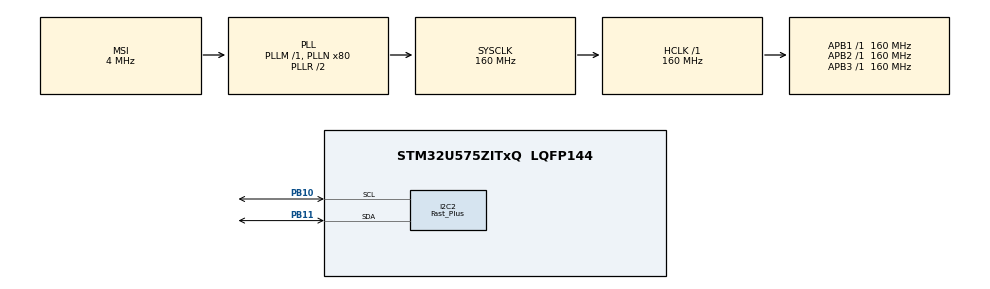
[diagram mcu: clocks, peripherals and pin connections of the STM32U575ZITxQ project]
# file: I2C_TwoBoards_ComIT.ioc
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CORTEX_M33_NS.userName=CORTEX_M33
I2C2.AddressingMode=I2C_ADDRESSINGMODE_10BIT
I2C2.Analog_Filter=I2C_ANALOGFILTER_ENABLE
I2C2.DualAddressMode=I2C_DUALADDRESS_DISABLE
I2C2.GeneralCallMode=I2C_GENERALCALL_DISABLE
I2C2.I2C_Coeff_DF=0
I2C2.I2C_Fall_Time=2
I2C2.I2C_Rise_Time=26
I2C2.I2C_Speed_Mode=I2C_Fast_Plus
I2C2.NoStretchMode=I2C_NOSTRETCH_DISABLE
I2C2.OwnAddress=I2C_ADDRESS
I2C2.Speed=1000
I2C2.Timing=0x00C01F67
Mcu.Family=STM32U5
Mcu.Name=STM32U575ZITxQ
Mcu.Package=LQFP144
Mcu.UserConstants=I2C_ADDRESS,0x30F
NVIC.I2C2_ER_IRQn=true\:0\:0\:false\:false\:true\:true\:true\:true
NVIC.I2C2_EV_IRQn=true\:0\:0\:false\:false\:true\:true\:true\:true
NVIC.PriorityGroup=NVIC_PRIORITYGROUP_4
PB10.GPIO_Pu=GPIO_PULLUP
PB10.Mode=I2C
PB10.Signal=I2C2_SCL
PB11.GPIO_Pu=GPIO_PULLUP
PB11.Mode=I2C
PB11.Signal=I2C2_SDA
PWR.PowerMode=PWR_SMPS_SUPPLY
ProjectManager.HeapSize=0x200
ProjectManager.StackSize=0x400
ProjectManager.TargetToolchain=EWARM V8.50
RCC.ADCFreq_Value=16000000
RCC.AHBFreq_Value=160000000
RCC.APB1Freq_Value=160000000
RCC.APB1TimFreq_Value=160000000
RCC.APB2Freq_Value=160000000
RCC.APB2TimFreq_Value=160000000
RCC.APB3Freq_Value=160000000
RCC.CortexFreq_Value=160000000
RCC.DACCLockSelectionVirtual=RCC_DAC1CLKSOURCE_LSI
RCC.DACCLockSelectionVirtualString=RCC_DAC1CLKSOURCE_LSI
RCC.EPOD_VALUE=4000000
RCC.HCLKFreq_Value=160000000
RCC.HSE_VALUE=16000000
RCC.HSI48_VALUE=48000000
RCC.HSI_VALUE=16000000
RCC.LSE_VALUE=32768
RCC.LSIDIV_VALUE=32000
RCC.MSI_VALUE=4000000
RCC.PLLN=80
RCC.SYSCLKFreq_VALUE=160000000
RCC.SYSCLKSource=RCC_SYSCLKSOURCE_PLLCLK
RCC.USBFreq_Value=48000000
RCC.VCOOutputFreq_Value=320000000
VP_ICACHE_VS_ICACHE.Mode=DirectMappedCache
VP_LPBAMQUEUE_VS_QUEUE.Mode=QUEUEMODE
VP_LPBAM_VS_SIG1.Mode=SmartRun
VP_LPBAM_VS_SIG4.Mode=LPDMA1
VP_PWR_VS_DBSignals.Mode=DisableDeadBatterySignals
VP_PWR_VS_LPOM.Mode=PowerOptimisation
VP_PWR_VS_SECSignals.Mode=Security/Privilege
board=custom

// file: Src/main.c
/* USER CODE BEGIN Header */
/**
  ******************************************************************************
  * @file    I2C/I2C_TwoBoards_ComIT/Src/main.c
  * @author  MCD Application Team
  * @brief   This sample code shows how to use STM32U5xx I2C HAL API to transmit
  *          and receive a data buffer with a communication process based on
  *          IT transfer.
  *          The communication is done using 2 Boards.
  ******************************************************************************
  * @attention
  *
  * Copyright (c) 2021 STMicroelectronics.
  * All rights reserved.
  *
  * This software is licensed under terms that can be found in the LICENSE file
  * in the root directory of this software component.
  * If no LICENSE file comes with this software, it is provided AS-IS.
  *
  ******************************************************************************
  */
/* USER CODE END Header */
#include "main.h"

/* USER CODE BEGIN PD */
/* Uncomment this line to use the board as master, if not it is used as slave */
//#define MASTER_BOARD
/* USER CODE END PD */

I2C_HandleTypeDef hi2c2;

/* USER CODE BEGIN PV */
/* Buffer used for transmission */
uint8_t aTxBuffer[] = " ****I2C_TwoBoards communication based on IT****  ****I2C_TwoBoards communication based on IT****  ****I2C_TwoBoards communication based on IT**** ";

/* Buffer used for reception */
uint8_t aRxBuffer[RXBUFFERSIZE];
/* USER CODE END PV */

void SystemClock_Config(void);
static void SystemPower_Config(void);
static void MX_GPIO_Init(void);
static void MX_I2C2_Init(void);
static void MX_ICACHE_Init(void);
/* USER CODE BEGIN PFP */
/* Private function prototypes -----------------------------------------------*/
static uint16_t Buffercmp(uint8_t *pBuffer1, uint8_t *pBuffer2, uint16_t BufferLength);

/* USER CODE END PFP */

int main(void)
{

  /* USER CODE BEGIN 1 */
  /* STM32U5xx HAL library initialization:
       - Configure the Flash prefetch
       - Configure the Systick to generate an interrupt each 1 msec
       - Set NVIC Group Priority to 3
       - Low Level Initialization
     */
  /* USER CODE END 1 */

  /* MCU Configuration--------------------------------------------------------*/

  /* Reset of all peripherals, Initializes the Flash interface and the Systick. */
  HAL_Init();

  /* Configure the System Power */
  SystemPower_Config();

  /* Configure the system clock */
  SystemClock_Config();

  /* Initialize all configured peripherals */
  MX_GPIO_Init();
  MX_I2C2_Init();
  MX_ICACHE_Init();
  /* USER CODE BEGIN 2 */
  /* Configure LED1 and LED3 */
  BSP_LED_Init(LED1);
  BSP_LED_Init(LED3);

#ifdef MASTER_BOARD

  /* Configure User push-button */
  BSP_PB_Init(BUTTON_USER, BUTTON_MODE_GPIO);
  /* USER CODE END 2 */

  /* Infinite loop */
  /* USER CODE BEGIN WHILE */
  /* Wait for User push-button press before starting the Communication */
  while (BSP_PB_GetState(BUTTON_USER) != GPIO_PIN_SET)
  {
  }

  /* Delay to avoid that possible signal rebound is taken as button release */
  HAL_Delay(50);

  /* Wait for User push-button release before starting the Communication */
  while (BSP_PB_GetState(BUTTON_USER) != GPIO_PIN_RESET)
  {
  }

  /* The board sends the message and expects to receive it back */

  /*##- Start the transmission process #####################################*/
  /* While the I2C in reception process, user can transmit data through
     "aTxBuffer" buffer */
  do
  {
    if (HAL_I2C_Master_Transmit_IT(&hi2c2, (uint16_t)I2C_ADDRESS, (uint8_t *)aTxBuffer, TXBUFFERSIZE) != HAL_OK)
    {
      /* Error_Handler() function is called when error occurs. */
      Error_Handler();
    }

    /*##- Wait for the end of the transfer #################################*/
    /*  Before starting a new communication transfer, you need to check the current
        state of the peripheral; if it's busy you need to wait for the end of current
        transfer before starting a new one.
        For simplicity reasons, this example is just waiting till the end of the
        transfer, but application may perform other tasks while transfer operation
        is ongoing. */
    while (HAL_I2C_GetState(&hi2c2) != HAL_I2C_STATE_READY)
    {
    }

    /* When Acknowledge failure occurs (Slave don't acknowledge it's address)
       Master restarts communication */
  }
  while (HAL_I2C_GetError(&hi2c2) == HAL_I2C_ERROR_AF);

  /* Wait for User push-button press before starting the Communication */
  while (BSP_PB_GetState(BUTTON_USER) != GPIO_PIN_SET)
  {
  }

  /* Delay to avoid that possible signal rebound is taken as button release */
  HAL_Delay(50);

  /* Wait for User push-button release before starting the Communication */
  while (BSP_PB_GetState(BUTTON_USER) != GPIO_PIN_RESET)
  {
  }

  /*##- Put I2C peripheral in reception process ###########################*/
  do
  {
    if (HAL_I2C_Master_Receive_IT(&hi2c2, (uint16_t)I2C_ADDRESS, (uint8_t *)aRxBuffer, RXBUFFERSIZE) != HAL_OK)
    {
      /* Error_Handler() function is called when error occurs. */
      Error_Handler();
    }

    /*##- Wait for the end of the transfer #################################*/
    /*  Before starting a new communication transfer, you need to check the current
        state of the peripheral; if it's busy you need to wait for the end of current
        transfer before starting a new one.
        For simplicity reasons, this example is just waiting till the end of the
        transfer, but application may perform other tasks while transfer operation
        is ongoing. */
    while (HAL_I2C_GetState(&hi2c2) != HAL_I2C_STATE_READY)
    {
    }

    /* When Acknowledge failure occurs (Slave don't acknowledge it's address)
       Master restarts communication */
  }
  while (HAL_I2C_GetError(&hi2c2) == HAL_I2C_ERROR_AF);

#else

  /* The board receives the message and sends it back */

  /*##- Put I2C peripheral in reception process ###########################*/
  if (HAL_I2C_Slave_Receive_IT(&hi2c2, (uint8_t *)aRxBuffer, RXBUFFERSIZE) != HAL_OK)
  {
    /* Transfer error in reception process */
    Error_Handler();
  }

  /*##- Wait for the end of the transfer ###################################*/
  /*  Before starting a new communication transfer, you need to check the current
      state of the peripheral; if it's busy you need to wait for the end of current
      transfer before starting a new one.
      For simplicity reasons, this example is just waiting till the end of the
      transfer, but application may perform other tasks while transfer operation
      is ongoing. */
  while (HAL_I2C_GetState(&hi2c2) != HAL_I2C_STATE_READY)
  {
  }

  /*##- Start the transmission process #####################################*/
  /* While the I2C in reception process, user can transmit data through
     "aTxBuffer" buffer */
  if (HAL_I2C_Slave_Transmit_IT(&hi2c2, (uint8_t *)aTxBuffer, TXBUFFERSIZE) != HAL_OK)
  {
    /* Transfer error in transmission process */
    Error_Handler();
  }

#endif /* MASTER_BOARD */

  /*##- Wait for the end of the transfer ###################################*/
  /*  Before starting a new communication transfer, you need to check the current
      state of the peripheral; if it's busy you need to wait for the end of current
      transfer before starting a new one.
      For simplicity reasons, this example is just waiting till the end of the
      transfer, but application may perform other tasks while transfer operation
      is ongoing. */
  while (HAL_I2C_GetState(&hi2c2) != HAL_I2C_STATE_READY)
  {
  }

  /*##- Compare the sent and received buffers ##############################*/
  if (Buffercmp((uint8_t *)aTxBuffer, (uint8_t *)aRxBuffer, RXBUFFERSIZE))
  {
    /* Processing Error */
    Error_Handler();
  }

  /* Infinite loop */
  while (1)
  {
    /* USER CODE END WHILE */

  }
}

void SystemClock_Config(void)
{
  RCC_OscInitTypeDef RCC_OscInitStruct = {0};
  RCC_ClkInitTypeDef RCC_ClkInitStruct = {0};

  /** Configure the main internal regulator output voltage
  */
  if (HAL_PWREx_ControlVoltageScaling(PWR_REGULATOR_VOLTAGE_SCALE1) != HAL_OK)
  {
    Error_Handler();
  }

  /** Initializes the CPU, AHB and APB buses clocks
  */
  RCC_OscInitStruct.OscillatorType = RCC_OSCILLATORTYPE_MSI;
  RCC_OscInitStruct.MSIState = RCC_MSI_ON;
  RCC_OscInitStruct.MSICalibrationValue = RCC_MSICALIBRATION_DEFAULT;
  RCC_OscInitStruct.MSIClockRange = RCC_MSIRANGE_4;
  RCC_OscInitStruct.PLL.PLLState = RCC_PLL_ON;
  RCC_OscInitStruct.PLL.PLLSource = RCC_PLLSOURCE_MSI;
  RCC_OscInitStruct.PLL.PLLMBOOST = RCC_PLLMBOOST_DIV1;
  RCC_OscInitStruct.PLL.PLLM = 1;
  RCC_OscInitStruct.PLL.PLLN = 80;
  RCC_OscInitStruct.PLL.PLLP = 2;
  RCC_OscInitStruct.PLL.PLLQ = 2;
  RCC_OscInitStruct.PLL.PLLR = 2;
  RCC_OscInitStruct.PLL.PLLRGE = RCC_PLLVCIRANGE_0;
  RCC_OscInitStruct.PLL.PLLFRACN = 0;
  if (HAL_RCC_OscConfig(&RCC_OscInitStruct) != HAL_OK)
  {
    Error_Handler();
  }

  /** Initializes the CPU, AHB and APB buses clocks
  */
  RCC_ClkInitStruct.ClockType = RCC_CLOCKTYPE_HCLK|RCC_CLOCKTYPE_SYSCLK
                              |RCC_CLOCKTYPE_PCLK1|RCC_CLOCKTYPE_PCLK2
                              |RCC_CLOCKTYPE_PCLK3;
  RCC_ClkInitStruct.SYSCLKSource = RCC_SYSCLKSOURCE_PLLCLK;
  RCC_ClkInitStruct.AHBCLKDivider = RCC_SYSCLK_DIV1;
  RCC_ClkInitStruct.APB1CLKDivider = RCC_HCLK_DIV1;
  RCC_ClkInitStruct.APB2CLKDivider = RCC_HCLK_DIV1;
  RCC_ClkInitStruct.APB3CLKDivider = RCC_HCLK_DIV1;

  if (HAL_RCC_ClockConfig(&RCC_ClkInitStruct, FLASH_LATENCY_4) != HAL_OK)
  {
    Error_Handler();
  }
}

/**
  * @brief Power Configuration
  * @retval None
  */
static void SystemPower_Config(void)
{

  /*
   * Disable the internal Pull-Up in Dead Battery pins of UCPD peripheral
   */
  HAL_PWREx_DisableUCPDDeadBattery();

  /*
   * Switch to SMPS regulator instead of LDO
   */
  if (HAL_PWREx_ConfigSupply(PWR_SMPS_SUPPLY) != HAL_OK)
  {
    Error_Handler();
  }
}

static void MX_I2C2_Init(void)
{

  hi2c2.Instance = I2C2;
  hi2c2.Init.Timing = 0x00C01F67;
  hi2c2.Init.OwnAddress1 = I2C_ADDRESS;
  hi2c2.Init.AddressingMode = I2C_ADDRESSINGMODE_10BIT;
  hi2c2.Init.DualAddressMode = I2C_DUALADDRESS_DISABLE;
  hi2c2.Init.OwnAddress2 = 0;
  hi2c2.Init.OwnAddress2Masks = I2C_OA2_NOMASK;
  hi2c2.Init.GeneralCallMode = I2C_GENERALCALL_DISABLE;
  hi2c2.Init.NoStretchMode = I2C_NOSTRETCH_DISABLE;
  if (HAL_I2C_Init(&hi2c2) != HAL_OK)
  {
    Error_Handler();
  }

  /** Configure Analogue filter
  */
  if (HAL_I2CEx_ConfigAnalogFilter(&hi2c2, I2C_ANALOGFILTER_ENABLE) != HAL_OK)
  {
    Error_Handler();
  }

  /** Configure Digital filter
  */
  if (HAL_I2CEx_ConfigDigitalFilter(&hi2c2, 0) != HAL_OK)
  {
    Error_Handler();
  }

  /** I2C Fast mode Plus enable
  */
  if (HAL_I2CEx_ConfigFastModePlus(&hi2c2, I2C_FASTMODEPLUS_ENABLE) != HAL_OK)
  {
    Error_Handler();
  }

}

static void MX_ICACHE_Init(void)
{

  /** Enable instruction cache in 1-way (direct mapped cache)
  */
  if (HAL_ICACHE_ConfigAssociativityMode(ICACHE_1WAY) != HAL_OK)
  {
    Error_Handler();
  }
  if (HAL_ICACHE_Enable() != HAL_OK)
  {
    Error_Handler();
  }

}

static void MX_GPIO_Init(void)
{

  /* GPIO Ports Clock Enable */
  __HAL_RCC_GPIOB_CLK_ENABLE();

}

/* USER CODE BEGIN 4 */
/**
  * @brief  Compares two buffers.
  * @param  pBuffer1, pBuffer2: buffers to be compared.
  * @param  BufferLength: buffer's length
  * @retval 0  : pBuffer1 identical to pBuffer2
  *         >0 : pBuffer1 differs from pBuffer2
  */
static uint16_t Buffercmp(uint8_t *pBuffer1, uint8_t *pBuffer2, uint16_t BufferLength)
{
  while (BufferLength--)
  {
    if ((*pBuffer1) != *pBuffer2)
    {
      return BufferLength;
    }
    pBuffer1++;
    pBuffer2++;
  }

  return 0;
}

/**
  * @brief  Tx Transfer completed callback.
  * @param  I2cHandle: I2C handle.
  * @note   This example shows a simple way to report end of IT Tx transfer, and
  *         you can add your own implementation.
  * @retval None
  */
#ifdef MASTER_BOARD
void HAL_I2C_MasterTxCpltCallback(I2C_HandleTypeDef *I2cHandle)
{
  /* Toggle LED1: Transfer in transmission process is correct */
  BSP_LED_Toggle(LED1);
}
#else
void HAL_I2C_SlaveTxCpltCallback(I2C_HandleTypeDef *I2cHandle)
{
  /* Toggle LED1: Transfer in transmission process is correct */
  BSP_LED_Toggle(LED1);
}
#endif /* MASTER_BOARD */

/**
  * @brief  Rx Transfer completed callback.
  * @param  I2cHandle: I2C handle
  * @note   This example shows a simple way to report end of IT Rx transfer, and
  *         you can add your own implementation.
  * @retval None
  */
#ifdef MASTER_BOARD
void HAL_I2C_MasterRxCpltCallback(I2C_HandleTypeDef *I2cHandle)
{
  /* Toggle LED1: Transfer in reception process is correct */
  BSP_LED_Toggle(LED1);
}
#else
void HAL_I2C_SlaveRxCpltCallback(I2C_HandleTypeDef *I2cHandle)
{
  /* Toggle LED1: Transfer in reception process is correct */
  BSP_LED_Toggle(LED1);
}
#endif /* MASTER_BOARD */

/**
  * @brief  I2C error callbacks.
  * @param  I2cHandle: I2C handle
  * @note   This example shows a simple way to report transfer error, and you can
  *         add your own implementation.
  * @retval None
  */
void HAL_I2C_ErrorCallback(I2C_HandleTypeDef *I2cHandle)
{
  /** Error_Handler() function is called when error occurs.
    * 1- When Slave doesn't acknowledge its address, Master restarts communication.
    * 2- When Master doesn't acknowledge the last data transferred, Slave doesn't care in this example.
    */
  if (HAL_I2C_GetError(I2cHandle) != HAL_I2C_ERROR_AF)
  {
    /* Turn Off LED1 */
    BSP_LED_Off(LED1);

    /* Turn On LED3 */
    BSP_LED_On(LED3);
  }
}

/* USER CODE END 4 */

void Error_Handler(void)
{
  /* USER CODE BEGIN Error_Handler_Debug */
  /* Turn LED3 on */
  BSP_LED_On(LED3);
  while (1)
  {
  }
  /* USER CODE END Error_Handler_Debug */
}
#ifdef USE_FULL_ASSERT
/**
  * @brief  Reports the name of the source file and the source line number
  *         where the assert_param error has occurred.
  * @param  file: pointer to the source file name
  * @param  line: assert_param error line source number
  * @retval None
  */
void assert_failed(uint8_t *file, uint32_t line)
{
  /* USER CODE BEGIN 6 */
  /* User can add his own implementation to report the file name and line number,
    ex: printf("Wrong parameters value: file %s on line %d\r\n", file, line) */
  Error_Handler();
  /* USER CODE END 6 */
}
#endif /* USE_FULL_ASSERT */
